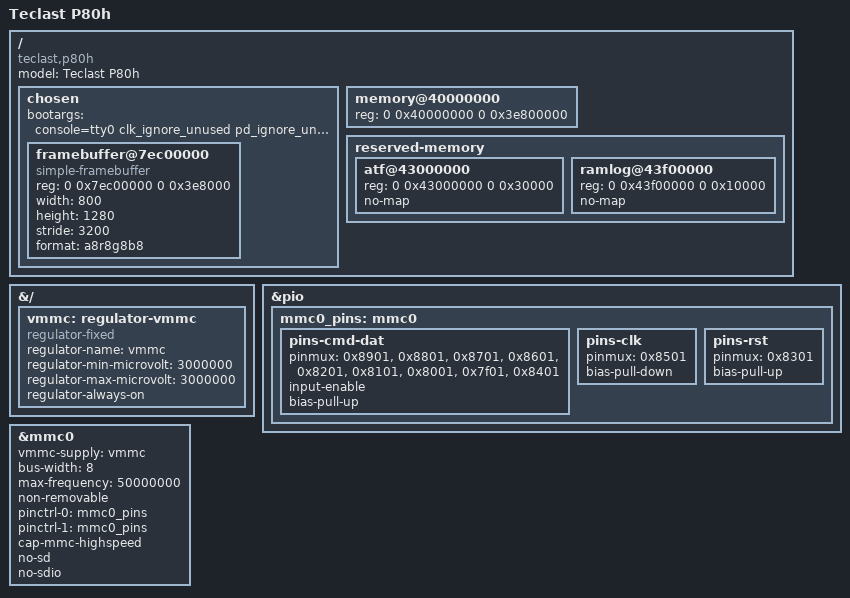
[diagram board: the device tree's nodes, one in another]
// SPDX-License-Identifier: GPL-2.0
/dts-v1/;
#include "mt8163.dtsi"

/ {
	model = "Teclast P80h";
	compatible = "teclast,p80h", "mediatek,mt8163";

	chosen {
		bootargs = "console=tty0 clk_ignore_unused pd_ignore_unused panic=10 initcall_debug ignore_loglevel";
		#address-cells = <2>;
		#size-cells = <2>;
		ranges;

		/* the panel is already lit by the bootloader (LK), keep scanning out its buffer */
		framebuffer@7ec00000 {
			compatible = "simple-framebuffer";
			reg = <0 0x7ec00000 0 0x3e8000>;
			width = <800>;
			height = <1280>;
			stride = <3200>;
			format = "a8r8g8b8";
		};
	};

	memory@40000000 {
		device_type = "memory";
		reg = <0 0x40000000 0 0x3e800000>;
	};

	reserved-memory {
		#address-cells = <2>;
		#size-cells = <2>;
		ranges;

		atf@43000000 { reg = <0 0x43000000 0 0x30000>; no-map; };
		ramlog@43f00000 { reg = <0 0x43f00000 0 0x10000>; no-map; };	/* persistent RAM console, see mt8163-ramlog.c */
	};
};

/* placeholder: no PMIC driver yet and the bootloader left the eMMC rail on. The core derives the host OCR mask
 * from this regulator and the card only advertises 2.7-3.1 V. */
&{/} {
	vmmc: regulator-vmmc {
		compatible = "regulator-fixed";
		regulator-name = "vmmc";
		regulator-min-microvolt = <3000000>;
		regulator-max-microvolt = <3000000>;
		regulator-always-on;
	};
};

&pio {
	/* pinmux cell = (pin << 8) | function, as in the vendor tree; pulls as the vendor board file sets them */
	mmc0_pins: mmc0 {
		pins-cmd-dat {
			pinmux = <0x8901>, <0x8801>, <0x8701>, <0x8601>, <0x8201>, <0x8101>, <0x8001>, <0x7f01>, <0x8401>;
			input-enable;
			bias-pull-up;
		};
		pins-clk {
			pinmux = <0x8501>;
			bias-pull-down;
		};
		pins-rst {
			pinmux = <0x8301>;
			bias-pull-up;
		};
	};
};

&mmc0 {
	vmmc-supply = <&vmmc>;
	bus-width = <8>;
	max-frequency = <50000000>;
	non-removable;
	pinctrl-names = "default", "state_uhs";
	pinctrl-0 = <&mmc0_pins>;
	pinctrl-1 = <&mmc0_pins>;
	cap-mmc-highspeed;
	no-sd;
	no-sdio;
	status = "okay";
};
